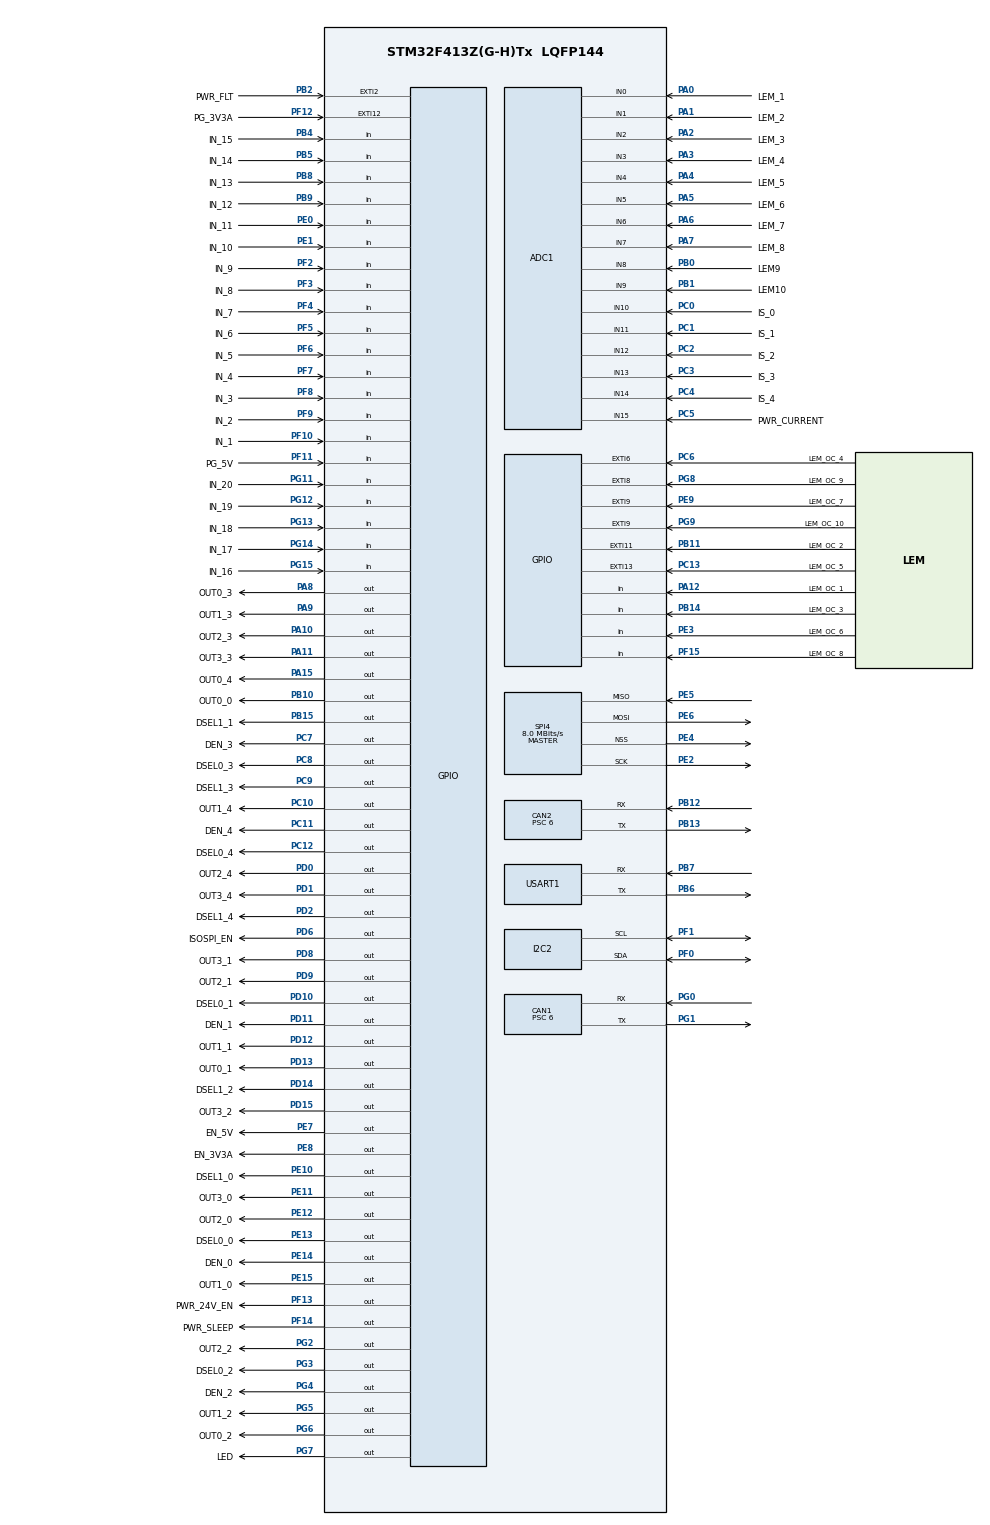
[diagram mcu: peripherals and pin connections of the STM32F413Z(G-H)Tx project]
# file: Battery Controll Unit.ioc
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ADC1.Channel-0\#ChannelRegularConversion=ADC_CHANNEL_0
ADC1.NbrOfConversionFlag=1
ADC1.Rank-0\#ChannelRegularConversion=1
ADC1.SamplingTime-0\#ChannelRegularConversion=ADC_SAMPLETIME_3CYCLES
ADC1.master=1
CAN1.BS1=CAN_BS1_13TQ
CAN1.BS2=CAN_BS2_2TQ
CAN1.CalculateBaudRate=166666
CAN1.CalculateTimeBit=6000
CAN1.CalculateTimeQuantum=375.0
CAN1.Prescaler=6
CAN2.BS1=CAN_BS1_13TQ
CAN2.BS2=CAN_BS2_2TQ
CAN2.CalculateBaudRate=166666
CAN2.CalculateTimeBit=6000
CAN2.CalculateTimeQuantum=375.0
CAN2.Prescaler=6
Mcu.Family=STM32F4
Mcu.Name=STM32F413Z(G-H)Tx
Mcu.Package=LQFP144
NVIC.PriorityGroup=NVIC_PRIORITYGROUP_4
PA0.GPIO_Label=LEM_1
PA0.Signal=ADCx_IN0
PA1.GPIO_Label=LEM_2
PA1.Signal=ADCx_IN1
PA10.GPIO_Label=OUT2_3
PA10.Signal=GPIO_Output
PA11.GPIO_Label=OUT3_3
PA11.Signal=GPIO_Output
PA12.GPIO_Label=LEM_OC_1
PA12.Signal=GPIO_Input
PA13.Mode=Trace_Asynchronous_SW
PA13.Signal=SYS_JTMS-SWDIO
PA14.Mode=Trace_Asynchronous_SW
PA14.Signal=SYS_JTCK-SWCLK
PA15.GPIO_Label=OUT0_4
PA15.Signal=GPIO_Output
PA2.GPIO_Label=LEM_3
PA2.Signal=ADCx_IN2
PA3.GPIO_Label=LEM_4
PA3.Signal=ADCx_IN3
PA4.GPIO_Label=LEM_5
PA4.Signal=ADCx_IN4
PA5.GPIO_Label=LEM_6
PA5.Signal=ADCx_IN5
PA6.GPIO_Label=LEM_7
PA6.Signal=ADCx_IN6
PA7.GPIO_Label=LEM_8
PA7.Signal=ADCx_IN7
PA8.GPIO_Label=OUT0_3
PA8.Signal=GPIO_Output
PA9.GPIO_Label=OUT1_3
PA9.Signal=GPIO_Output
PB0.GPIO_Label=LEM9
PB0.Signal=ADCx_IN8
PB1.GPIO_Label=LEM10
PB1.Signal=ADCx_IN9
PB10.GPIO_Label=OUT0_0
PB10.Signal=GPIO_Output
PB11.GPIO_Label=LEM_OC_2
PB11.Signal=GPXTI11
PB12.Mode=CAN_Activate
PB12.Signal=CAN2_RX
PB13.Mode=CAN_Activate
PB13.Signal=CAN2_TX
PB14.GPIO_Label=LEM_OC_3
PB14.Signal=GPIO_Input
PB15.GPIO_Label=DSEL1_1
PB15.Signal=GPIO_Output
PB2.GPIO_Label=PWR_FLT
PB2.Signal=GPXTI2
PB3.Mode=Trace_Asynchronous_SW
PB3.Signal=SYS_JTDO-SWO
PB4.GPIO_Label=IN_15
PB4.Signal=GPIO_Input
PB5.GPIO_Label=IN_14
PB5.Signal=GPIO_Input
PB6.Mode=Asynchronous
PB6.Signal=USART1_TX
PB7.Mode=Asynchronous
PB7.Signal=USART1_RX
PB8.GPIO_Label=IN_13
PB8.Signal=GPIO_Input
PB9.GPIO_Label=IN_12
PB9.Signal=GPIO_Input
PC0.GPIO_Label=IS_0
PC0.Signal=ADCx_IN10
PC1.GPIO_Label=IS_1
PC1.Signal=ADCx_IN11
PC10.GPIO_Label=OUT1_4
PC10.Signal=GPIO_Output
PC11.GPIO_Label=DEN_4
PC11.Signal=GPIO_Output
PC12.GPIO_Label=DSEL0_4
PC12.Signal=GPIO_Output
PC13.GPIO_Label=LEM_OC_5
PC13.Signal=GPXTI13
PC14-OSC32_IN.Mode=LSE-External-Oscillator
PC14-OSC32_IN.Signal=RCC_OSC32_IN
PC15-OSC32_OUT.Mode=LSE-External-Oscillator
PC15-OSC32_OUT.Signal=RCC_OSC32_OUT
PC2.GPIO_Label=IS_2
PC2.Signal=ADCx_IN12
PC3.GPIO_Label=IS_3
PC3.Signal=ADCx_IN13
PC4.GPIO_Label=IS_4
PC4.Signal=ADCx_IN14
PC5.GPIO_Label=PWR_CURRENT
PC5.Signal=ADCx_IN15
PC6.GPIO_Label=LEM_OC_4
PC6.Signal=GPXTI6
PC7.GPIO_Label=DEN_3
PC7.Signal=GPIO_Output
PC8.GPIO_Label=DSEL0_3
PC8.Signal=GPIO_Output
PC9.GPIO_Label=DSEL1_3
PC9.Signal=GPIO_Output
PD0.GPIO_Label=OUT2_4
PD0.Signal=GPIO_Output
PD1.GPIO_Label=OUT3_4
PD1.Signal=GPIO_Output
PD10.GPIO_Label=DSEL0_1
PD10.Signal=GPIO_Output
PD11.GPIO_Label=DEN_1
PD11.Signal=GPIO_Output
PD12.GPIO_Label=OUT1_1
PD12.Signal=GPIO_Output
PD13.GPIO_Label=OUT0_1
PD13.Signal=GPIO_Output
PD14.GPIO_Label=DSEL1_2
PD14.Signal=GPIO_Output
PD15.GPIO_Label=OUT3_2
PD15.Signal=GPIO_Output
PD2.GPIO_Label=DSEL1_4
PD2.Signal=GPIO_Output
PD6.GPIO_Label=ISOSPI_EN
PD6.Signal=GPIO_Output
PD8.GPIO_Label=OUT3_1
PD8.Signal=GPIO_Output
PD9.GPIO_Label=OUT2_1
PD9.Signal=GPIO_Output
PE0.GPIO_Label=IN_11
PE0.Signal=GPIO_Input
PE1.GPIO_Label=IN_10
PE1.Signal=GPIO_Input
PE10.GPIO_Label=DSEL1_0
PE10.Signal=GPIO_Output
PE11.GPIO_Label=OUT3_0
PE11.Signal=GPIO_Output
PE12.GPIO_Label=OUT2_0
PE12.Signal=GPIO_Output
PE13.GPIO_Label=DSEL0_0
PE13.Signal=GPIO_Output
PE14.GPIO_Label=DEN_0
PE14.Signal=GPIO_Output
PE15.GPIO_Label=OUT1_0
PE15.Signal=GPIO_Output
PE2.Mode=Full_Duplex_Master
PE2.Signal=SPI4_SCK
PE3.GPIO_Label=LEM_OC_6
PE3.Signal=GPIO_Input
PE4.Mode=NSS_Signal_Hard_Output
PE4.Signal=SPI4_NSS
PE5.Mode=Full_Duplex_Master
PE5.Signal=SPI4_MISO
PE6.Mode=Full_Duplex_Master
PE6.Signal=SPI4_MOSI
PE7.GPIO_Label=EN_5V
PE7.Signal=GPIO_Output
PE8.GPIO_Label=EN_3V3A
PE8.Signal=GPIO_Output
PE9.GPIO_Label=LEM_OC_7
PE9.Signal=GPXTI9
PF0.Mode=I2C
PF0.Signal=I2C2_SDA
PF1.Mode=I2C
PF1.Signal=I2C2_SCL
PF10.GPIO_Label=IN_1
PF10.Signal=GPIO_Input
PF11.GPIO_Label=PG_5V
PF11.Signal=GPIO_Input
PF12.GPIO_Label=PG_3V3A
PF12.Signal=GPXTI12
PF13.GPIO_Label=PWR_24V_EN
PF13.Signal=GPIO_Output
PF14.GPIO_Label=PWR_SLEEP
PF14.Signal=GPIO_Output
PF15.GPIO_Label=LEM_OC_8
PF15.Signal=GPIO_Input
PF2.GPIO_Label=IN_9
PF2.Signal=GPIO_Input
PF3.GPIO_Label=IN_8
PF3.Signal=GPIO_Input
PF4.GPIO_Label=IN_7
PF4.Signal=GPIO_Input
PF5.GPIO_Label=IN_6
PF5.Signal=GPIO_Input
PF6.GPIO_Label=IN_5
PF6.Signal=GPIO_Input
PF7.GPIO_Label=IN_4
PF7.Signal=GPIO_Input
PF8.GPIO_Label=IN_3
PF8.Signal=GPIO_Input
PF9.GPIO_Label=IN_2
PF9.Signal=GPIO_Input
PG0.Mode=CAN_Activate
PG0.Signal=CAN1_RX
PG1.Mode=CAN_Activate
PG1.Signal=CAN1_TX
PG11.GPIO_Label=IN_20
PG11.Signal=GPIO_Input
PG12.GPIO_Label=IN_19
PG12.Signal=GPIO_Input
PG13.GPIO_Label=IN_18
PG13.Signal=GPIO_Input
PG14.GPIO_Label=IN_17
PG14.Signal=GPIO_Input
PG15.GPIO_Label=IN_16
PG15.Signal=GPIO_Input
PG2.GPIO_Label=OUT2_2
PG2.Signal=GPIO_Output
PG3.GPIO_Label=DSEL0_2
PG3.Signal=GPIO_Output
PG4.GPIO_Label=DEN_2
PG4.Signal=GPIO_Output
PG5.GPIO_Label=OUT1_2
PG5.Signal=GPIO_Output
PG6.GPIO_Label=OUT0_2
PG6.Signal=GPIO_Output
PG7.GPIO_Label=LED
PG7.Signal=GPIO_Output
PG8.GPIO_Label=LEM_OC_9
PG8.Signal=GPXTI8
PG9.GPIO_Label=LEM_OC_10
PG9.Signal=GPXTI9
PH0\ -\ OSC_IN.Mode=HSE-External-Oscillator
PH0\ -\ OSC_IN.Signal=RCC_OSC_IN
PH1\ -\ OSC_OUT.Mode=HSE-External-Oscillator
PH1\ -\ OSC_OUT.Signal=RCC_OSC_OUT
ProjectManager.HeapSize=0x200
ProjectManager.StackSize=0x400
ProjectManager.TargetToolchain=STM32CubeIDE
RCC.CortexFreq_Value=16000000
RCC.USBFreq_Value=96000000
RCC.VCOOutputFreq_Value=192000000
SH.ADCx_IN0.0=ADC1_IN0,IN0
SH.ADCx_IN1.0=ADC1_IN1,IN1
SH.ADCx_IN10.0=ADC1_IN10,IN10
SH.ADCx_IN11.0=ADC1_IN11,IN11
SH.ADCx_IN12.0=ADC1_IN12,IN12
SH.ADCx_IN13.0=ADC1_IN13,IN13
SH.ADCx_IN14.0=ADC1_IN14,IN14
SH.ADCx_IN15.0=ADC1_IN15,IN15
SH.ADCx_IN2.0=ADC1_IN2,IN2
SH.ADCx_IN3.0=ADC1_IN3,IN3
SH.ADCx_IN4.0=ADC1_IN4,IN4
SH.ADCx_IN5.0=ADC1_IN5,IN5
SH.ADCx_IN6.0=ADC1_IN6,IN6
SH.ADCx_IN7.0=ADC1_IN7,IN7
SH.ADCx_IN8.0=ADC1_IN8,IN8
SH.ADCx_IN9.0=ADC1_IN9,IN9
SPI4.CalculateBaudRate=8.0 MBits/s
SPI4.Direction=SPI_DIRECTION_2LINES
SPI4.Mode=SPI_MODE_MASTER
SPI4.VirtualNSS=VM_NSSHARD
SPI4.VirtualType=VM_MASTER
USART1.VirtualMode=VM_ASYNC
board=custom

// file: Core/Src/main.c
/* USER CODE BEGIN Header */
/**
  ******************************************************************************
  * @file           : main.c
  * @brief          : Main program body
  ******************************************************************************
  * @attention
  *
  * Copyright (c) 2025 STMicroelectronics.
  * All rights reserved.
  *
  * This software is licensed under terms that can be found in the LICENSE file
  * in the root directory of this software component.
  * If no LICENSE file comes with this software, it is provided AS-IS.
  *
  ******************************************************************************
  */
/* USER CODE END Header */
#include "main.h"

/* USER CODE BEGIN Includes */
#include "btt6200_4esa.h"
#include "btt6200_config.h"
#include "tmp1075.h"
#include "cy15b256j.h"
#include "temp_logger.h"
#include "lem_hoys.h"
#include "lem_config.h"
#include "bmu_can.h"
#include "adc_dma.h"
#include "can_diagnostics.h"
#include "dcdc_controller.h"
#include "dcdc_diagnostics.h"
#include <string.h>
#include <stdio.h>
#include <stdlib.h>
#include <stdbool.h>
#include <math.h>

/* USER CODE END Includes */

ADC_HandleTypeDef hadc1;
DMA_HandleTypeDef hdma_adc1;

CAN_HandleTypeDef hcan1;
CAN_HandleTypeDef hcan2;

I2C_HandleTypeDef hi2c2;

SPI_HandleTypeDef hspi4;

UART_HandleTypeDef huart1;

/* USER CODE BEGIN PV */
static TMP1075_HandleTypeDef htmp1075;
static CY15B256J_HandleTypeDef hfram;
static TempLogger_HandleTypeDef htemplogger;
static BMU_CAN_HandleTypeDef hbmucan;
ADC_DMA_HandleTypeDef hadc_dma;  // Non-static - used by lem_hoys.c and btt6200_4esa.c

// CAN message counters
static uint32_t can_heartbeat_counter = 0;

/* USER CODE END PV */

void SystemClock_Config(void);
static void MX_GPIO_Init(void);
static void MX_ADC1_Init(void);
static void MX_CAN1_Init(void);
static void MX_CAN2_Init(void);
static void MX_SPI4_Init(void);
static void MX_USART1_UART_Init(void);
static void MX_I2C2_Init(void);

/* USER CODE BEGIN 0 */

// ADC konstante
#define ADC_VREF_UV            3300000UL  // 3.3V v mikrovolti
#define ADC_BITS               12
#define ADC_MAX_VALUE          4095UL     // (1 << 12) - 1
#define ADC_TO_UV(adc_val)     (((adc_val) * ADC_VREF_UV) / ADC_MAX_VALUE)

// Power sense konstante
#define PWR_SENSE_RESISTOR_MOHM 100      // 0.1 ohm = 100 milliohm
#define PWR_SENSE_GAIN         50
#define PWR_VOLTAGE_DIV        5000UL    // Voltage divider

// I2C adresi
#define TMP1075_I2C_ADDR       (0x48 << 1)
#define FRAM_I2C_ADDR          (0x50 << 1)

// LEM senzorji
#define NUM_LEM_SENSORS        10
#define NUM_ADC_CHANNELS       8

// Timing konstante
#define MAIN_LOOP_DELAY_MS     100
#define CAN_TX_TIMEOUT_MS      100

/* USER CODE END 0 */

int main(void)
{

  /* USER CODE BEGIN 1 */
  char uart_buf[256];  // Povečan buffer za preprečitev overflow

  /* USER CODE END 1 */

  /* MCU Configuration--------------------------------------------------------*/

  /* Reset of all peripherals, Initializes the Flash interface and the Systick. */
  HAL_Init();

  /* Configure the system clock */
  SystemClock_Config();

  /* Initialize all configured peripherals */
  MX_GPIO_Init();
  MX_ADC1_Init();
  MX_CAN1_Init();
  MX_CAN2_Init();
  MX_SPI4_Init();
  MX_USART1_UART_Init();
  MX_I2C2_Init();
  /* USER CODE BEGIN 2 */

  // Debug: Preveri I2C2 devices
  uint8_t msg[] = "\r\n=== BMU IOC Initialization ===\r\n";
  HAL_UART_Transmit(&huart1, msg, sizeof(msg)-1, 100);

  // I2C scan za TMP1075
  if (HAL_I2C_IsDeviceReady(&hi2c2, TMP1075_I2C_ADDR, 3, 100) == HAL_OK) {
      uint8_t found[] = "TMP1075 detected at 0x48\r\n";
      HAL_UART_Transmit(&huart1, found, sizeof(found)-1, 100);
  } else {
      uint8_t notfound[] = "TMP1075 NOT detected at 0x48!\r\n";
      HAL_UART_Transmit(&huart1, notfound, sizeof(notfound)-1, 100);
  }

  // Inicializacija TMP1075
  HAL_StatusTypeDef tmp_status = TMP1075_Init(&htmp1075, &hi2c2, TMP1075_I2C_ADDR >> 1);
  if (tmp_status == HAL_OK) {
      uint8_t init_ok[] = "TMP1075 initialized OK\r\n";
      HAL_UART_Transmit(&huart1, init_ok, sizeof(init_ok)-1, 100);

      // Nastavi low temperature threshold na 0°C (alert pri < 0°C)
      if (TMP1075_SetLowThreshold(&htmp1075, 0.0f) == HAL_OK) {
          uint8_t thresh_ok[] = "Low threshold set to 0.0C\r\n";
          HAL_UART_Transmit(&huart1, thresh_ok, sizeof(thresh_ok)-1, 100);
      }
  } else {
      uint8_t init_fail[] = "TMP1075 initialization FAILED!\r\n";
      HAL_UART_Transmit(&huart1, init_fail, sizeof(init_fail)-1, 100);
  }

  // I2C scan za FRAM CY15B256J
  if (HAL_I2C_IsDeviceReady(&hi2c2, FRAM_I2C_ADDR, 3, 100) == HAL_OK) {
      uint8_t fram_found[] = "FRAM CY15B256J detected at 0x50\r\n";
      HAL_UART_Transmit(&huart1, fram_found, sizeof(fram_found)-1, 100);
  } else {
      uint8_t fram_notfound[] = "FRAM NOT detected at 0x50!\r\n";
      HAL_UART_Transmit(&huart1, fram_notfound, sizeof(fram_notfound)-1, 100);
  }

  // Inicializacija FRAM
  HAL_StatusTypeDef fram_status = CY15B256J_Init(&hfram, &hi2c2, FRAM_I2C_ADDR >> 1, NULL, 0);
  if (fram_status == HAL_OK) {
      uint8_t fram_ok[] = "FRAM initialized OK\r\n";
      HAL_UART_Transmit(&huart1, fram_ok, sizeof(fram_ok)-1, 100);

      // Inicializacija Temperature Logger (reset_stats = false za ohranitev podatkov)
      if (TempLogger_Init(&htemplogger, &hfram, false) == HAL_OK) {
          uint8_t logger_ok[] = "Temperature Logger initialized OK\r\n";
          HAL_UART_Transmit(&huart1, logger_ok, sizeof(logger_ok)-1, 100);

          // Izpiši trenutne statistike
          TempLog_Stats_t stats;
          if (TempLogger_GetStats(&htemplogger, &stats) == HAL_OK) {
              (void)snprintf(uart_buf, sizeof(uart_buf), "Stored samples: %lu, Alerts: %lu\r\n",
                      stats.sample_count, stats.alert_count);
              HAL_UART_Transmit(&huart1, (uint8_t*)uart_buf, strlen(uart_buf), 100);

              if (stats.sample_count > 0U) {
                  int32_t min_frac = stats.min_temp % 100;
                  int32_t max_frac = stats.max_temp % 100;
                  min_frac = (min_frac < 0) ? -min_frac : min_frac;
                  max_frac = (max_frac < 0) ? -max_frac : max_frac;
                  (void)snprintf(uart_buf, sizeof(uart_buf), "Min: %d.%02dC, Max: %d.%02dC\r\n",
                          (int)(stats.min_temp/100), (int)min_frac,
                          (int)(stats.max_temp/100), (int)max_frac);
                  (void)HAL_UART_Transmit(&huart1, (uint8_t*)uart_buf, (uint16_t)strlen(uart_buf), 100);
              }
          }
      }
  } else {
      uint8_t fram_fail[] = "FRAM initialization FAILED!\r\n";
      HAL_UART_Transmit(&huart1, fram_fail, sizeof(fram_fail)-1, 100);
  }

  /* Inicializacija LEM HOYS current sensorjev */
  uint8_t lem_msg[] = "\r\n=== LEM HOYS Current Sensors ===\r\n";
  HAL_UART_Transmit(&huart1, lem_msg, sizeof(lem_msg)-1, 100);

  if (LEM_Config_Init(&hadc1) == HAL_OK) {
      uint8_t lem_ok[] = "LEM sensors initialized OK\r\n";
      HAL_UART_Transmit(&huart1, lem_ok, sizeof(lem_ok)-1, 100);

      // Kalibriraj vse senzorje (POMEMBNO: mora biti 0A!)
      uint8_t cal_msg[] = "Calibrating LEM sensors (ensure 0A)...\r\n";
      HAL_UART_Transmit(&huart1, cal_msg, sizeof(cal_msg)-1, 100);

      if (LEM_Config_CalibrateAll(50) == HAL_OK) {
          uint8_t cal_ok[] = "LEM calibration complete\r\n";
          HAL_UART_Transmit(&huart1, cal_ok, sizeof(cal_ok)-1, 100);
      } else {
          uint8_t cal_fail[] = "LEM calibration FAILED!\r\n";
          HAL_UART_Transmit(&huart1, cal_fail, sizeof(cal_fail)-1, 100);
      }
  } else {
      uint8_t lem_fail[] = "LEM initialization FAILED!\r\n";
      HAL_UART_Transmit(&huart1, lem_fail, sizeof(lem_fail)-1, 100);
  }

  /* Inicializacija CAN protokola (500 kbps) */
  uint8_t can_msg[] = "\r\n=== CAN Bus Protocol ===\r\n";
  HAL_UART_Transmit(&huart1, can_msg, sizeof(can_msg)-1, 100);

  // Debug: Preveri CAN1 state pred inicializacijo
  (void)snprintf(uart_buf, sizeof(uart_buf), "CAN1 State before init: 0x%02X\r\n", hcan1.State);
  HAL_UART_Transmit(&huart1, (uint8_t*)uart_buf, strlen(uart_buf), 100);

  /* TESTING MODE: Set to 1 to enable LOOPBACK mode (test without other CAN nodes) */
  #if 0
  // Switch CAN2 to LOOPBACK mode for solo testing without ACK errors
  uint8_t loopback_msg[] = "*** CAN2 LOOPBACK MODE ENABLED ***\r\n";
  HAL_UART_Transmit(&huart1, loopback_msg, sizeof(loopback_msg)-1, 100);
  uint8_t loopback_info[] = "CAN2 will TX and RX its own messages (no external bus needed)\r\n";
  HAL_UART_Transmit(&huart1, loopback_info, sizeof(loopback_info)-1, 100);

  hcan2.Init.Mode = CAN_MODE_LOOPBACK;  // LOOPBACK: TX -> RX internally
  if (HAL_CAN_Init(&hcan2) != HAL_OK) {
      uint8_t err[] = "Failed to switch CAN2 to LOOPBACK mode!\r\n";
      HAL_UART_Transmit(&huart1, err, sizeof(err)-1, 100);
  } else {
      uint8_t ok[] = "CAN2 LOOPBACK mode configured successfully\r\n";
      HAL_UART_Transmit(&huart1, ok, sizeof(ok)-1, 100);
  }
  #endif

  if (BMU_CAN_Init(&hbmucan, &hcan1, &hcan2) == HAL_OK) {
      uint8_t can_ok[] = "CAN bus initialized OK (500 kbps)\r\n";
      HAL_UART_Transmit(&huart1, can_ok, sizeof(can_ok)-1, 100);

      /* TEST CAN1 TX: Standard ID test */
      {
          CAN_TxHeaderTypeDef test_header;
          uint8_t test_data[8] = {0x11, 0x22, 0x33, 0x44, 0x55, 0x66, 0x77, 0x88};
          uint32_t test_mailbox;
          HAL_StatusTypeDef test_status;

          uint8_t test_msg[] = "\r\n>>> CAN1 TEST TX START <<<\r\n";
          HAL_UART_Transmit(&huart1, test_msg, sizeof(test_msg)-1, 100);

          /* Standard ID test message */
          test_header.StdId = 0x123;  /* Test Standard ID */
          test_header.IDE = CAN_ID_STD;
          test_header.RTR = CAN_RTR_DATA;
          test_header.DLC = 8;
          test_header.TransmitGlobalTime = DISABLE;

          test_status = HAL_CAN_AddTxMessage(&hcan1, &test_header, test_data, &test_mailbox);

          if (test_status == HAL_OK) {
              (void)snprintf(uart_buf, sizeof(uart_buf),
                  "✓ CAN1 TEST TX SUCCESS! StdID:0x%03lX Mailbox:%lu\r\n",
                  test_header.StdId, test_mailbox);
              HAL_UART_Transmit(&huart1, (uint8_t*)uart_buf, strlen(uart_buf), 100);
          } else {
              (void)snprintf(uart_buf, sizeof(uart_buf),
                  "✗ CAN1 TEST TX FAILED! Status:%d\r\n", test_status);
              HAL_UART_Transmit(&huart1, (uint8_t*)uart_buf, strlen(uart_buf), 100);
          }

          uint8_t test_end[] = ">>> CAN1 TEST TX END <<<\r\n\r\n";
          HAL_UART_Transmit(&huart1, test_end, sizeof(test_end)-1, 100);
      }

      /* TEST CAN2 TX: Extended ID test */
      {
          CAN_TxHeaderTypeDef test_header;
          uint8_t test_data[8] = {0xAA, 0xBB, 0xCC, 0xDD, 0x11, 0x22, 0x33, 0x44};
          uint32_t test_mailbox;
          HAL_StatusTypeDef test_status;

          uint8_t test_msg[] = ">>> CAN2 TEST TX START <<<\r\n";
          HAL_UART_Transmit(&huart1, test_msg, sizeof(test_msg)-1, 100);

          /* Extended ID test message */
          test_header.ExtId = 0x18FF5500;  /* Test Extended ID */
          test_header.IDE = CAN_ID_EXT;
          test_header.RTR = CAN_RTR_DATA;
          test_header.DLC = 8;
          test_header.TransmitGlobalTime = DISABLE;

          /* Check CAN2 state before sending */
          (void)snprintf(uart_buf, sizeof(uart_buf), "CAN2 State: 0x%02X\r\n", hcan2.State);
          HAL_UART_Transmit(&huart1, (uint8_t*)uart_buf, strlen(uart_buf), 100);

          uint32_t can2_error = HAL_CAN_GetError(&hcan2);
          (void)snprintf(uart_buf, sizeof(uart_buf), "CAN2 Error: 0x%08lX\r\n", can2_error);
          HAL_UART_Transmit(&huart1, (uint8_t*)uart_buf, strlen(uart_buf), 100);

          uint32_t free_boxes = HAL_CAN_GetTxMailboxesFreeLevel(&hcan2);
          (void)snprintf(uart_buf, sizeof(uart_buf), "CAN2 Free TX Mailboxes: %lu\r\n", free_boxes);
          HAL_UART_Transmit(&huart1, (uint8_t*)uart_buf, strlen(uart_buf), 100);

          /* Send test message on CAN2 */
          test_status = HAL_CAN_AddTxMessage(&hcan2, &test_header, test_data, &test_mailbox);

          if (test_status == HAL_OK) {
              (void)snprintf(uart_buf, sizeof(uart_buf),
                  "✓ CAN2 AddTxMessage OK! ExtID:0x%08lX Mailbox:%lu\r\n",
                  test_header.ExtId, test_mailbox);
              HAL_UART_Transmit(&huart1, (uint8_t*)uart_buf, strlen(uart_buf), 100);

              /* Wait for TX to complete and check result */
              HAL_Delay(100);  /* Give time for TX to complete */

              can2_error = HAL_CAN_GetError(&hcan2);
              (void)snprintf(uart_buf, sizeof(uart_buf), "CAN2 Error after TX attempt: 0x%08lX\r\n", can2_error);
              HAL_UART_Transmit(&huart1, (uint8_t*)uart_buf, strlen(uart_buf), 100);

              /* Decode CAN2 error codes */
              if (can2_error == 0x00000000UL) {
                  uint8_t ok[] = "✓ NO ERRORS - CAN2 TX successful!\r\n";
                  HAL_UART_Transmit(&huart1, ok, sizeof(ok)-1, 100);
              } else {
                  if ((can2_error & 0x00000004UL) != 0UL) {  /* HAL_CAN_ERROR_ACK */
                      uint8_t ack_err[] = "✗ ACK ERROR - No device on bus acknowledged message!\r\n";
                      HAL_UART_Transmit(&huart1, ack_err, sizeof(ack_err)-1, 100);
                      uint8_t ack_fix[] = "  FIX: Connect another CAN device OR enable LOOPBACK mode\r\n";
                      HAL_UART_Transmit(&huart1, ack_fix, sizeof(ack_fix)-1, 100);
                  }
                  if ((can2_error & 0x00000010UL) != 0UL) {  /* HAL_CAN_ERROR_BOF */
                      uint8_t bof_err[] = "✗ BUS-OFF - Too many errors, CAN2 disabled!\r\n";
                      HAL_UART_Transmit(&huart1, bof_err, sizeof(bof_err)-1, 100);
                  }
                  if ((can2_error & 0x00000001UL) != 0UL) {  /* HAL_CAN_ERROR_EWG */
                      uint8_t ewg_err[] = "⚠ ERROR WARNING - Error count high\r\n";
                      HAL_UART_Transmit(&huart1, ewg_err, sizeof(ewg_err)-1, 100);
                  }
              }
          } else {
              (void)snprintf(uart_buf, sizeof(uart_buf),
                  "✗ CAN2 AddTxMessage FAILED! Status:%d\r\n", test_status);
              HAL_UART_Transmit(&huart1, (uint8_t*)uart_buf, strlen(uart_buf), 100);

              /* Print detailed error */
              can2_error = HAL_CAN_GetError(&hcan2);
              (void)snprintf(uart_buf, sizeof(uart_buf), "CAN2 Error code: 0x%08lX\r\n", can2_error);
              HAL_UART_Transmit(&huart1, (uint8_t*)uart_buf, strlen(uart_buf), 100);
          }

          uint8_t test_end[] = ">>> CAN2 TEST TX END <<<\r\n\r\n";
          HAL_UART_Transmit(&huart1, test_end, sizeof(test_end)-1, 100);
      }

      // Debug: Preveri CAN1 error code
      uint32_t can_error = HAL_CAN_GetError(&hcan1);
      (void)snprintf(uart_buf, sizeof(uart_buf), "CAN1 Error Code: 0x%08lX\r\n", can_error);
      HAL_UART_Transmit(&huart1, (uint8_t*)uart_buf, strlen(uart_buf), 100);

      /* DIAGNOSTICS: Set to 0 to disable diagnostics for testing */
      #if 0  // DISABLED for debugging - diagnostika lahko povzroča probleme
      CAN_RunDiagnostics(&hcan1, &huart1);
      #else
      uint8_t diag_skip[] = "CAN diagnostics SKIPPED (disabled for debugging)\r\n";
      HAL_UART_Transmit(&huart1, diag_skip, sizeof(diag_skip)-1, 100);
      #endif
  } else {
      uint8_t can_fail[] = "CAN initialization FAILED!\r\n";
      HAL_UART_Transmit(&huart1, can_fail, sizeof(can_fail)-1, 100);

      // Debug: Izpiši error code
      uint32_t can_error = HAL_CAN_GetError(&hcan1);
      (void)snprintf(uart_buf, sizeof(uart_buf), "CAN1 Error Code: 0x%08lX\r\n", can_error);
      HAL_UART_Transmit(&huart1, (uint8_t*)uart_buf, strlen(uart_buf), 100);
      (void)snprintf(uart_buf, sizeof(uart_buf), "CAN1 State: 0x%02X\r\n", hcan1.State);
      HAL_UART_Transmit(&huart1, (uint8_t*)uart_buf, strlen(uart_buf), 100);
  }

  /* Inicializacija ADC DMA - avtomatsko kontinuirano branje vseh 16 kanalov */
  if (ADC_DMA_Init(&hadc_dma, &hadc1, &hdma_adc1) == HAL_OK) {
    ADC_DMA_Start(&hadc_dma);
  }

  /* inicializacija BTT6200 modulov */
  BTT6200_Config_Init(&hadc1);   // ali &hadc, isto kot si nastavil v config.c
  BTT6200_Init(&btt6200_modules[0]);

  /* Inicializacija DC/DC kontrolerja (CAN2) */
  uint8_t dcdc_msg[] = "\r\n=== DC/DC Converter Control ===\r\n";
  HAL_UART_Transmit(&huart1, dcdc_msg, sizeof(dcdc_msg)-1, 100);

  if (DCDC_Init()) {
      uint8_t dcdc_ok[] = "DC/DC controller initialized OK\r\n";
      HAL_UART_Transmit(&huart1, dcdc_ok, sizeof(dcdc_ok)-1, 100);

      /* Konfiguriraj oba pretvornika: 24V, 10A, Bus1toBus2 */
      DCDC_Config_t dcdc_config;
      dcdc_config.converter_mode = DCDC_MODE_BUS1_TO_BUS2;
      dcdc_config.control_type = DCDC_CTRL_TYPE_VBUS2_LIM;
      dcdc_config.voltage_setpoint = DCDC_SETPOINT_24V;    /* 24.0V */
      dcdc_config.current_limit = DCDC_CURRENT_LIMIT_10A;  /* 10.0A */
      dcdc_config.start_command = DCDC_CMD_STOP;           /* Začni v STOP */

      if (DCDC_Configure(0, &dcdc_config) && DCDC_Configure(1, &dcdc_config)) {
          uint8_t dcdc_cfg_ok[] = "DC/DC converters configured: 24V, 10A, Bus1toBus2\r\n";
          HAL_UART_Transmit(&huart1, dcdc_cfg_ok, sizeof(dcdc_cfg_ok)-1, 100);

          /* AKTIVIRAJ CAN2 TX: Start oba pretvornika za testiranje */
          if (DCDC_Start(0) && DCDC_Start(1)) {
              uint8_t dcdc_start_ok[] = "DC/DC converters STARTED - CAN2 TX active!\r\n";
              HAL_UART_Transmit(&huart1, dcdc_start_ok, sizeof(dcdc_start_ok)-1, 100);
          } else {
              uint8_t dcdc_start_fail[] = "WARNING: DC/DC start failed - CAN2 TX inactive!\r\n";
              HAL_UART_Transmit(&huart1, dcdc_start_fail, sizeof(dcdc_start_fail)-1, 100);
          }
      }
  } else {
      uint8_t dcdc_fail[] = "DC/DC controller initialization FAILED!\r\n";
      HAL_UART_Transmit(&huart1, dcdc_fail, sizeof(dcdc_fail)-1, 100);
  }

  /* Inicializacija DC/DC diagnostike (CAN1) */
  if (DCDC_Diag_Init()) {
      uint8_t diag_ok[] = "DC/DC diagnostics initialized OK (CAN1)\r\n";
      HAL_UART_Transmit(&huart1, diag_ok, sizeof(diag_ok)-1, 100);
  }

  uint8_t ready[] = "\r\n*** System Ready ***\r\n\r\n";
  HAL_UART_Transmit(&huart1, ready, sizeof(ready)-1, 100);

  /* USER CODE END 2 */

  /* Infinite loop */
  /* USER CODE BEGIN WHILE */
  uint32_t loop_iteration = 0;
  uint32_t last_slow_task_tick = 0;  /* Timestamp za počasne naloge (1Hz) */

  while (1)
  {
    /* USER CODE END WHILE */

    /* USER CODE BEGIN 3 */
	  uint32_t current_tick = HAL_GetTick();
	  bool execute_slow_tasks = false;

	  /* Preveri če je čas za počasne naloge (1x na sekundo) */
	  if ((current_tick - last_slow_task_tick) >= 1000U) {
	      execute_slow_tasks = true;
	      last_slow_task_tick = current_tick;
	      loop_iteration++;
	  }

	  /* HITRE NALOGE: Izvajaj vsakih 10-20ms */

	  // ========== DC/DC Periodic Tasks (20ms timing interno) ==========
	  DCDC_PeriodicTask();         /* CAN2: Control frame vsakih 20ms */
	  DCDC_Diag_PeriodicTask();    /* CAN1: Diagnostika vsakih 100ms */

	  /* POČASNE NALOGE: Izvajaj 1x na sekundo */
	  if (execute_slow_tasks) {
	      float tC;
	      int16_t temp_x100;
	      bool is_alert;

	      // Debug output (samo vsakih 10 sekund)
	      if (loop_iteration % 10U == 1U) {
	          (void)snprintf(uart_buf, sizeof(uart_buf), "\r\n=== Loop %lu ===\r\n", loop_iteration);
	          HAL_UART_Transmit(&huart1, (uint8_t*)uart_buf, strlen(uart_buf), 100);
	      }

	      HAL_GPIO_WritePin(PWR_24V_EN_GPIO_Port, PWR_24V_EN_Pin, SET);
	      HAL_GPIO_WritePin(PWR_SLEEP_GPIO_Port, PWR_SLEEP_Pin, SET);
	      HAL_GPIO_TogglePin(LED_GPIO_Port, LED_Pin);  // LED toggle za heartbeat

	      // Preberi in izpiši temperaturo
	      tC = 0.0f;
	      temp_x100 = 0;
	      is_alert = false;
	      if (TMP1075_ReadTemperature(&htmp1075, &tC) == HAL_OK) {
	          // Uspešno branje temperature
	          int32_t temp_int = (int32_t)tC;
	          int32_t temp_frac = (int32_t)((tC - (float)temp_int) * 100.0f);
	          if (temp_frac < 0) {
	              temp_frac = -temp_frac;  // Absolutna vrednost za decimale
	          }

	          // Konvertiraj v int16_t (°C × 100) za shranjevanje v FRAM
	          temp_x100 = (int16_t)(tC * 100.0f);
	          is_alert = (tC < 0.0f);

	          // Shrani v FRAM (če je inicializiran)
	          if (htemplogger.is_initialized != false) {
	              (void)TempLogger_LogTemperature(&htemplogger, temp_x100, is_alert);
	          }

	          // ALERT: Temperatura pod 0°C
	          if (is_alert) {
	              (void)snprintf(uart_buf, sizeof(uart_buf), "*** ALERT! Temperature: %d.%02d C (BELOW 0C!) ***\r\n", temp_int, temp_frac);
	              HAL_UART_Transmit(&huart1, (uint8_t*)uart_buf, strlen(uart_buf), 100);
	              // Prižgi LED - hitro utripanje za alarm
	              HAL_GPIO_WritePin(LED_GPIO_Port, LED_Pin, SET);
	              HAL_Delay(100);
	              HAL_GPIO_WritePin(LED_GPIO_Port, LED_Pin, RESET);
	              HAL_Delay(100);
	              HAL_GPIO_WritePin(LED_GPIO_Port, LED_Pin, SET);
	          } else {
	              (void)snprintf(uart_buf, sizeof(uart_buf), "Temperature: %d.%02d C\r\n", temp_int, temp_frac);
	              HAL_UART_Transmit(&huart1, (uint8_t*)uart_buf, strlen(uart_buf), 100);
	          }
	      } else {
	          uint8_t err[] = "Temperature read FAILED!\r\n";
	          HAL_UART_Transmit(&huart1, err, sizeof(err)-1, 100);
	      }

	        // ADC DMA Debug: Prikaz ADC surovih vrednosti in DMA statistike
	        #if 0  // Set to 1 to enable ADC DMA debug output
	        if (hadc_dma.is_initialized) {
	            uint32_t conv_count, error_count;
	            if (ADC_DMA_GetStats(&hadc_dma, &conv_count, &error_count) == HAL_OK) {
	                (void)snprintf(uart_buf, sizeof(uart_buf), "[ADC DMA] Conv: %lu, Errors: %lu\r\n", conv_count, error_count);
	                HAL_UART_Transmit(&huart1, (uint8_t*)uart_buf, strlen(uart_buf), 100);
	            }

	            // Prikaz surovih ADC vrednosti za LEM senzorje 1-3
	            uint16_t adc_value;
	            for (uint8_t i = 0; i < 3; i++) {
	                if (ADC_DMA_GetValue(&hadc_dma, (ADC_DMA_Channel_t)i, &adc_value) == HAL_OK) {
	                    (void)snprintf(uart_buf, sizeof(uart_buf), "ADC_CH%d: %4u  ", i, adc_value);
	                    HAL_UART_Transmit(&huart1, (uint8_t*)uart_buf, strlen(uart_buf), 100);
	                }
	            }
	            uint8_t nl[] = "\r\n";
	            HAL_UART_Transmit(&huart1, nl, sizeof(nl)-1, 100);
	        }
	        #endif

	        // Preberi LEM sensorje (prikaz prvih 3 za demo)
	        float lem_currents[3];
	        for (uint8_t i = 0; i < 3; i++) {
	            if (LEM_Config_ReadCurrentFiltered(i, &lem_currents[i]) == HAL_OK) {
	                int curr_int = (int)lem_currents[i];
	                int curr_frac = (int)(fabsf(lem_currents[i] - curr_int) * 1000);
	                (void)snprintf(uart_buf, sizeof(uart_buf), "LEM_%d: %d.%03d A  ", i+1, curr_int, curr_frac);
	                HAL_UART_Transmit(&huart1, (uint8_t*)uart_buf, strlen(uart_buf), 100);
	            }
	        }
	        uint8_t newline[] = "\r\n";
	        HAL_UART_Transmit(&huart1, newline, sizeof(newline)-1, 100);

	        // Preveri overcurrent na vseh LEM senzorjih
	        uint16_t oc_flags = 0;
	        LEM_Config_CheckOvercurrents(&oc_flags);
	        if (oc_flags != 0) {
	            (void)snprintf(uart_buf, sizeof(uart_buf), "*** OVERCURRENT DETECTED! Flags: 0x%04X ***\r\n", oc_flags);
	            HAL_UART_Transmit(&huart1, (uint8_t*)uart_buf, strlen(uart_buf), 100);
	        }

	        // ========== CAN Bus Data Transmission ==========
	        // Check and recover from CAN errors (BUS-OFF, etc.)
	        if (hbmucan.is_initialized) {
	            BMU_CAN_CheckAndRecover(&hbmucan);
	        }

	        // Debug: Check CAN state (only print every 10th or if error detected)
	        HAL_CAN_StateTypeDef can_state = HAL_CAN_GetState(&hcan1);
	        uint32_t free_mailboxes = HAL_CAN_GetTxMailboxesFreeLevel(&hcan1);
	        uint32_t can_error = HAL_CAN_GetError(&hcan1);

	        if (loop_iteration % 10 == 1 || can_error != 0) {
	            (void)snprintf(uart_buf, sizeof(uart_buf), "[CAN] Init:%d State:0x%02X FreeMB:%lu Err:0x%lX\r\n",
	                          hbmucan.is_initialized, can_state, free_mailboxes, can_error);
	            HAL_UART_Transmit(&huart1, (uint8_t*)uart_buf, strlen(uart_buf), 10);
	        }

	        if (hbmucan.is_initialized) {
	            // Only print TX start message every 10th iteration
	            if (loop_iteration % 10 == 1) {
	                uint8_t tx_start[] = "[CAN] TX sequence...\r\n";
	                HAL_UART_Transmit(&huart1, tx_start, sizeof(tx_start)-1, 10);
	            }
	            // 1. Pošlji Temperature message (0x101)
	            BMU_Temperature_Msg_t temp_msg = {0};
	            temp_msg.temperature_C = temp_x100;
	            temp_msg.alert_flag = is_alert ? 1 : 0;
	            temp_msg.sensor_status = 0;
	            if (htemplogger.is_initialized) {
	                TempLog_Stats_t stats;
	                if (TempLogger_GetStats(&htemplogger, &stats) == HAL_OK) {
	                    temp_msg.min_temp_C = stats.min_temp;
	                    temp_msg.max_temp_C = stats.max_temp;
	                }
	            }
	            BMU_CAN_SendTemperature(&hbmucan, &temp_msg);

	            // 2. Pošlji Power Supply Status (0x102)
	            BMU_PowerSupply_Msg_t pwr_msg = {0};
	            pwr_msg.pg_5v = HAL_GPIO_ReadPin(PG_5V_GPIO_Port, PG_5V_Pin);
	            pwr_msg.pg_3v3a = HAL_GPIO_ReadPin(PG_3V3A_GPIO_Port, PG_3V3A_Pin);
	            pwr_msg.pwr_sleep_state = HAL_GPIO_ReadPin(PWR_SLEEP_GPIO_Port, PWR_SLEEP_Pin);

	            /* PWR_CURRENT: Read from ADC_IN15 (PC5) via DMA
	             * PWR_VOLTAGE: Not configured in hardware - using nominal value
	             *
	             * NOTE: Za pravo merjenje 24V napetosti je potreben:
	             * 1. Voltage divider circuit (npr. 10k/1k = 11:1 ratio za 24V->2.18V)
	             * 2. Dodaten ADC kanal v CubeMX konfiguraciji
	             * 3. Kalibracija voltage divider faktorja
	             */

	            // Read PWR_CURRENT from ADC DMA buffer (IN15)
	            uint16_t pwr_current_adc = 0;
	            if (hadc_dma.is_initialized) {
	                ADC_DMA_GetValue(&hadc_dma, ADC_DMA_PWR_CURRENT, &pwr_current_adc);
	            }

	            // Convert ADC to current (assuming current sense resistor circuit)
	            // TODO: Adjust conversion factor based on hardware design
	            // Typical: V_adc = (I_load * R_sense * Gain) where R_sense ~0.1 ohm, Gain=50
	            // I_load = V_adc / (R_sense * Gain)
	            // For 3.3V ref, 12-bit ADC: V_adc = (adc_value * 3300) / 4095
	            uint32_t voltage_uV = ADC_TO_UV(pwr_current_adc);
	            pwr_msg.pwr_current_mA = (uint16_t)(voltage_uV / PWR_VOLTAGE_DIV);  // R_sense*Gain = 0.1*50 = 5

	            // PWR_VOLTAGE: Use nominal value (no ADC sensing configured)
	            // Alternative: Could monitor PG_24V flag and return 0 if power fault
	            pwr_msg.pwr_voltage_mV = 24000U;  // Nominal 24V (hardware sensing not implemented)
	            pwr_msg.pg_24v = (pwr_msg.pwr_voltage_mV > 20000U) ? 1U : 0U;
	            BMU_CAN_SendPowerSupply(&hbmucan, &pwr_msg);

	            // 3. Pošlji Input States (0x103)
	            BMU_InputStates_Msg_t input_msg = {0};
	            input_msg.input_states = 0;
	            // Preberi vseh 20 digitalnih inputov (IN_1 do IN_20)
	            // OPOMBA: Za optimizacijo bi lahko uporabili direkten dostop do GPIO IDR register,
	            // če so vsi pini na istem portu. Trenutna implementacija je generična.
	            if (HAL_GPIO_ReadPin(IN_1_GPIO_Port, IN_1_Pin)) input_msg.input_states |= (1 << 0);
	            if (HAL_GPIO_ReadPin(IN_2_GPIO_Port, IN_2_Pin)) input_msg.input_states |= (1 << 1);
	            if (HAL_GPIO_ReadPin(IN_3_GPIO_Port, IN_3_Pin)) input_msg.input_states |= (1 << 2);
	            if (HAL_GPIO_ReadPin(IN_4_GPIO_Port, IN_4_Pin)) input_msg.input_states |= (1 << 3);
	            if (HAL_GPIO_ReadPin(IN_5_GPIO_Port, IN_5_Pin)) input_msg.input_states |= (1 << 4);
	            if (HAL_GPIO_ReadPin(IN_6_GPIO_Port, IN_6_Pin)) input_msg.input_states |= (1 << 5);
	            if (HAL_GPIO_ReadPin(IN_7_GPIO_Port, IN_7_Pin)) input_msg.input_states |= (1 << 6);
	            if (HAL_GPIO_ReadPin(IN_8_GPIO_Port, IN_8_Pin)) input_msg.input_states |= (1 << 7);
	            if (HAL_GPIO_ReadPin(IN_9_GPIO_Port, IN_9_Pin)) input_msg.input_states |= (1 << 8);
	            if (HAL_GPIO_ReadPin(IN_10_GPIO_Port, IN_10_Pin)) input_msg.input_states |= (1 << 9);
	            if (HAL_GPIO_ReadPin(IN_11_GPIO_Port, IN_11_Pin)) input_msg.input_states |= (1 << 10);
	            if (HAL_GPIO_ReadPin(IN_12_GPIO_Port, IN_12_Pin)) input_msg.input_states |= (1 << 11);
	            if (HAL_GPIO_ReadPin(IN_13_GPIO_Port, IN_13_Pin)) input_msg.input_states |= (1 << 12);
	            if (HAL_GPIO_ReadPin(IN_14_GPIO_Port, IN_14_Pin)) input_msg.input_states |= (1 << 13);
	            if (HAL_GPIO_ReadPin(IN_15_GPIO_Port, IN_15_Pin)) input_msg.input_states |= (1 << 14);
	            if (HAL_GPIO_ReadPin(IN_16_GPIO_Port, IN_16_Pin)) input_msg.input_states |= (1 << 15);
	            if (HAL_GPIO_ReadPin(IN_17_GPIO_Port, IN_17_Pin)) input_msg.input_states |= (1 << 16);
	            if (HAL_GPIO_ReadPin(IN_18_GPIO_Port, IN_18_Pin)) input_msg.input_states |= (1 << 17);
	            if (HAL_GPIO_ReadPin(IN_19_GPIO_Port, IN_19_Pin)) input_msg.input_states |= (1 << 18);
	            if (HAL_GPIO_ReadPin(IN_20_GPIO_Port, IN_20_Pin)) input_msg.input_states |= (1 << 19);
	            BMU_CAN_SendInputStates(&hbmucan, &input_msg);

	            // 4. Pošlji LEM Current messages (0x110-0x112) - FIXED
	            float all_lem_currents[NUM_LEM_SENSORS];
	            LEM_Config_ReadAllCurrents(all_lem_currents);

	            BMU_LEM_Current_Msg_t lem_msg1 = {0};
	            lem_msg1.current_1_mA = (int16_t)(all_lem_currents[0] * 1000);
	            lem_msg1.current_2_mA = (int16_t)(all_lem_currents[1] * 1000);
	            lem_msg1.current_3_mA = (int16_t)(all_lem_currents[2] * 1000);
	            lem_msg1.current_4_mA = (int16_t)(all_lem_currents[3] * 1000);
	            BMU_CAN_SendLEMCurrent(&hbmucan, CAN_ID_LEM_CURRENT_1, &lem_msg1);

	            BMU_LEM_Current_Msg_t lem_msg2 = {0};
	            lem_msg2.current_1_mA = (int16_t)(all_lem_currents[4] * 1000);
	            lem_msg2.current_2_mA = (int16_t)(all_lem_currents[5] * 1000);
	            lem_msg2.current_3_mA = (int16_t)(all_lem_currents[6] * 1000);
	            lem_msg2.current_4_mA = (int16_t)(all_lem_currents[7] * 1000);
	            BMU_CAN_SendLEMCurrent(&hbmucan, CAN_ID_LEM_CURRENT_2, &lem_msg2);

	            BMU_LEM_Current_Msg_t lem_msg3 = {0};
	            lem_msg3.current_1_mA = (int16_t)(all_lem_currents[8] * 1000);
	            lem_msg3.current_2_mA = (int16_t)(all_lem_currents[9] * 1000);
	            lem_msg3.current_3_mA = 0;
	            lem_msg3.current_4_mA = 0;
	            BMU_CAN_SendLEMCurrent(&hbmucan, CAN_ID_LEM_CURRENT_3, &lem_msg3);

	            // 5. Pošlji BTT6200 Detailed Status (0x124-0x128) - vseh 20 outputov
	            for (uint8_t msg_idx = 0; msg_idx < 5; msg_idx++) {
	                BMU_BTT6200_Detailed_Msg_t btt_detail = {0};
	                uint8_t base_out = msg_idx * 4;

	                // STATUS_OK means channel is enabled and working
	                btt_detail.out0_state = (BTT6200_Config_GetStatus(base_out + 0) == BTT6200_STATUS_OK) ? 1U : 0U;
	                btt_detail.out1_state = (BTT6200_Config_GetStatus(base_out + 1) == BTT6200_STATUS_OK) ? 1U : 0U;
	                btt_detail.out2_state = (BTT6200_Config_GetStatus(base_out + 2) == BTT6200_STATUS_OK) ? 1U : 0U;
	                btt_detail.out3_state = (BTT6200_Config_GetStatus(base_out + 3) == BTT6200_STATUS_OK) ? 1U : 0U;

	                uint32_t curr_mA;
	                BTT6200_Config_ReadCurrent(base_out + 0, &curr_mA);
	                btt_detail.out0_current_mA = (uint16_t)curr_mA;
	                BTT6200_Config_ReadCurrent(base_out + 1, &curr_mA);
	                btt_detail.out1_current_mA = (uint16_t)curr_mA;

	                BMU_CAN_SendBTTDetailed(&hbmucan, CAN_ID_BTT6200_DETAIL_1 + msg_idx, &btt_detail);
	            }

	            // 6. Pošlji Heartbeat (0x1FF)
	            BMU_CAN_SendHeartbeat(&hbmucan, can_heartbeat_counter++);

	            // Debug: CAN TX complete - print stats only every 10th iteration
	            if (loop_iteration % 10 == 1) {
	                uint32_t tx_count, rx_count, err_count;
	                BMU_CAN_GetStats(&hbmucan, &tx_count, &rx_count, &err_count);
	                (void)snprintf(uart_buf, sizeof(uart_buf), "[CAN] Stats: TX:%lu RX:%lu ERR:%lu\r\n",
	                              tx_count, rx_count, err_count);
	                HAL_UART_Transmit(&huart1, (uint8_t*)uart_buf, strlen(uart_buf), 10);
	            }
	        } else {
	            uint8_t not_init[] = "[CAN] NOT INITIALIZED - skipping TX!\r\n";
	            HAL_UART_Transmit(&huart1, not_init, sizeof(not_init)-1, 100);
	        }

	  }  /* Konec execute_slow_tasks bloka */

	  // ========== Main Loop Delay ==========
	  /* KRITIČNO: Kratek delay (10ms) za 50Hz loop rate */
	  /* To omogoči DCDC_PeriodicTask() pošiljanje na 20ms! */
	  HAL_Delay(10);

#if 0  /* TEST CODE - Disabled for production */
	  // BTT6200 channel test sequence (enable manually for testing)
	  BTT6200_SetChannel(&btt6200_modules[0], BTT6200_CH0, true);
	  BTT6200_SetChannel(&btt6200_modules[0], BTT6200_CH1, true);
	  BTT6200_SetChannel(&btt6200_modules[0], BTT6200_CH2, true);
	  BTT6200_SetChannel(&btt6200_modules[0], BTT6200_CH3, true);
	  HAL_Delay(1000);
	  BTT6200_SetChannel(&btt6200_modules[1], BTT6200_CH0, true);
	  BTT6200_SetChannel(&btt6200_modules[1], BTT6200_CH1, true);
	  BTT6200_SetChannel(&btt6200_modules[1], BTT6200_CH2, true);
	  BTT6200_SetChannel(&btt6200_modules[1], BTT6200_CH3, true);
	  HAL_Delay(1000);
	  BTT6200_SetChannel(&btt6200_modules[2], BTT6200_CH0, true);
	  BTT6200_SetChannel(&btt6200_modules[2], BTT6200_CH1, true);
	  BTT6200_SetChannel(&btt6200_modules[2], BTT6200_CH2, true);
	  BTT6200_SetChannel(&btt6200_modules[2], BTT6200_CH3, true);
	  HAL_Delay(1000);
	  BTT6200_SetChannel(&btt6200_modules[3], BTT6200_CH0, true);
	  BTT6200_SetChannel(&btt6200_modules[3], BTT6200_CH1, true);
	  BTT6200_SetChannel(&btt6200_modules[3], BTT6200_CH2, true);
	  BTT6200_SetChannel(&btt6200_modules[3], BTT6200_CH3, true);
	  HAL_Delay(1000);
	  BTT6200_SetChannel(&btt6200_modules[4], BTT6200_CH0, true);
	  BTT6200_SetChannel(&btt6200_modules[4], BTT6200_CH1, true);
	  BTT6200_SetChannel(&btt6200_modules[4], BTT6200_CH2, true);
	  BTT6200_SetChannel(&btt6200_modules[4], BTT6200_CH3, true);
	  uint32_t i_mA;
	  if (BTT6200_ReadChannelCurrent(&btt6200_modules[1], BTT6200_CH1, &i_mA) == HAL_OK) {
	      // i_mA = tok v mA (po tvoji formuli v driverju)
	  }
#endif  /* TEST CODE */

  }
  /* USER CODE END 3 */
}

void SystemClock_Config(void)
{
  RCC_OscInitTypeDef RCC_OscInitStruct = {0};
  RCC_ClkInitTypeDef RCC_ClkInitStruct = {0};

  /** Configure the main internal regulator output voltage
  */
  __HAL_RCC_PWR_CLK_ENABLE();
  __HAL_PWR_VOLTAGESCALING_CONFIG(PWR_REGULATOR_VOLTAGE_SCALE1);

  /** Initializes the RCC Oscillators according to the specified parameters
  * in the RCC_OscInitTypeDef structure.
  */
  RCC_OscInitStruct.OscillatorType = RCC_OSCILLATORTYPE_HSI;
  RCC_OscInitStruct.HSIState = RCC_HSI_ON;
  RCC_OscInitStruct.HSICalibrationValue = RCC_HSICALIBRATION_DEFAULT;
  RCC_OscInitStruct.PLL.PLLState = RCC_PLL_NONE;
  if (HAL_RCC_OscConfig(&RCC_OscInitStruct) != HAL_OK)
  {
    Error_Handler();
  }

  /** Initializes the CPU, AHB and APB buses clocks
  */
  RCC_ClkInitStruct.ClockType = RCC_CLOCKTYPE_HCLK|RCC_CLOCKTYPE_SYSCLK
                              |RCC_CLOCKTYPE_PCLK1|RCC_CLOCKTYPE_PCLK2;
  RCC_ClkInitStruct.SYSCLKSource = RCC_SYSCLKSOURCE_HSI;
  RCC_ClkInitStruct.AHBCLKDivider = RCC_SYSCLK_DIV1;
  RCC_ClkInitStruct.APB1CLKDivider = RCC_HCLK_DIV1;
  RCC_ClkInitStruct.APB2CLKDivider = RCC_HCLK_DIV1;

  if (HAL_RCC_ClockConfig(&RCC_ClkInitStruct, FLASH_LATENCY_0) != HAL_OK)
  {
    Error_Handler();
  }
}

static void MX_ADC1_Init(void)
{

  ADC_ChannelConfTypeDef sConfig = {0};

  /** Configure the global features of the ADC (Clock, Resolution, Data Alignment and number of conversion)
  */
  hadc1.Instance = ADC1;
  hadc1.Init.ClockPrescaler = ADC_CLOCK_SYNC_PCLK_DIV2;
  hadc1.Init.Resolution = ADC_RESOLUTION_12B;
  hadc1.Init.ScanConvMode = ENABLE;                    // Enable for multiple channels
  hadc1.Init.ContinuousConvMode = ENABLE;              // Enable for continuous conversion
  hadc1.Init.DiscontinuousConvMode = DISABLE;
  hadc1.Init.ExternalTrigConvEdge = ADC_EXTERNALTRIGCONVEDGE_NONE;
  hadc1.Init.ExternalTrigConv = ADC_SOFTWARE_START;
  hadc1.Init.DataAlign = ADC_DATAALIGN_RIGHT;
  hadc1.Init.NbrOfConversion = 16;                     // 16 channels total
  hadc1.Init.DMAContinuousRequests = ENABLE;           // Enable DMA continuous requests
  hadc1.Init.EOCSelection = ADC_EOC_SEQ_CONV;          // End of sequence
  if (HAL_ADC_Init(&hadc1) != HAL_OK)
  {
    Error_Handler();
  }

  /** Configure all 16 ADC channels in sequence
   *  Channels mapped to:
   *  - IN0-IN9: LEM sensors 1-10 (PA0-PA7, PB0-PB1)
   *  - IN10-IN14: BTT6200 IS channels 0-4 (PC0-PC4)
   *  - IN15: Power current (PC5)
  */
  sConfig.SamplingTime = ADC_SAMPLETIME_15CYCLES;

  // LEM sensors (IN0-IN9)
  sConfig.Channel = ADC_CHANNEL_0; sConfig.Rank = 1;
  if (HAL_ADC_ConfigChannel(&hadc1, &sConfig) != HAL_OK) { Error_Handler(); }

  sConfig.Channel = ADC_CHANNEL_1; sConfig.Rank = 2;
  if (HAL_ADC_ConfigChannel(&hadc1, &sConfig) != HAL_OK) { Error_Handler(); }

  sConfig.Channel = ADC_CHANNEL_2; sConfig.Rank = 3;
  if (HAL_ADC_ConfigChannel(&hadc1, &sConfig) != HAL_OK) { Error_Handler(); }

  sConfig.Channel = ADC_CHANNEL_3; sConfig.Rank = 4;
  if (HAL_ADC_ConfigChannel(&hadc1, &sConfig) != HAL_OK) { Error_Handler(); }

  sConfig.Channel = ADC_CHANNEL_4; sConfig.Rank = 5;
  if (HAL_ADC_ConfigChannel(&hadc1, &sConfig) != HAL_OK) { Error_Handler(); }

  sConfig.Channel = ADC_CHANNEL_5; sConfig.Rank = 6;
  if (HAL_ADC_ConfigChannel(&hadc1, &sConfig) != HAL_OK) { Error_Handler(); }

  sConfig.Channel = ADC_CHANNEL_6; sConfig.Rank = 7;
  if (HAL_ADC_ConfigChannel(&hadc1, &sConfig) != HAL_OK) { Error_Handler(); }

  sConfig.Channel = ADC_CHANNEL_7; sConfig.Rank = 8;
  if (HAL_ADC_ConfigChannel(&hadc1, &sConfig) != HAL_OK) { Error_Handler(); }

  sConfig.Channel = ADC_CHANNEL_8; sConfig.Rank = 9;
  if (HAL_ADC_ConfigChannel(&hadc1, &sConfig) != HAL_OK) { Error_Handler(); }

  sConfig.Channel = ADC_CHANNEL_9; sConfig.Rank = 10;
  if (HAL_ADC_ConfigChannel(&hadc1, &sConfig) != HAL_OK) { Error_Handler(); }

  // BTT6200 IS channels (IN10-IN14)
  sConfig.Channel = ADC_CHANNEL_10; sConfig.Rank = 11;
  if (HAL_ADC_ConfigChannel(&hadc1, &sConfig) != HAL_OK) { Error_Handler(); }

  sConfig.Channel = ADC_CHANNEL_11; sConfig.Rank = 12;
  if (HAL_ADC_ConfigChannel(&hadc1, &sConfig) != HAL_OK) { Error_Handler(); }

  sConfig.Channel = ADC_CHANNEL_12; sConfig.Rank = 13;
  if (HAL_ADC_ConfigChannel(&hadc1, &sConfig) != HAL_OK) { Error_Handler(); }

  sConfig.Channel = ADC_CHANNEL_13; sConfig.Rank = 14;
  if (HAL_ADC_ConfigChannel(&hadc1, &sConfig) != HAL_OK) { Error_Handler(); }

  sConfig.Channel = ADC_CHANNEL_14; sConfig.Rank = 15;
  if (HAL_ADC_ConfigChannel(&hadc1, &sConfig) != HAL_OK) { Error_Handler(); }

  // Power current (IN15)
  sConfig.Channel = ADC_CHANNEL_15; sConfig.Rank = 16;
  if (HAL_ADC_ConfigChannel(&hadc1, &sConfig) != HAL_OK) { Error_Handler(); }

}

static void MX_CAN1_Init(void)
{

  hcan1.Instance = CAN1;
  hcan1.Init.Prescaler = 2;  // 500 kbps: 16MHz / (2 * 16) = 500 kbps
  hcan1.Init.Mode = CAN_MODE_NORMAL;
  hcan1.Init.SyncJumpWidth = CAN_SJW_1TQ;
  hcan1.Init.TimeSeg1 = CAN_BS1_13TQ;
  hcan1.Init.TimeSeg2 = CAN_BS2_2TQ;
  hcan1.Init.TimeTriggeredMode = DISABLE;
  hcan1.Init.AutoBusOff = ENABLE;  // Auto recovery iz bus-off
  hcan1.Init.AutoWakeUp = DISABLE;
  hcan1.Init.AutoRetransmission = ENABLE;  // Ponovno pošiljanje
  hcan1.Init.ReceiveFifoLocked = DISABLE;
  hcan1.Init.TransmitFifoPriority = DISABLE;
  if (HAL_CAN_Init(&hcan1) != HAL_OK)
  {
    Error_Handler();
  }

}

static void MX_CAN2_Init(void)
{

  hcan2.Instance = CAN2;
  hcan2.Init.Prescaler = 2;  // 500 kbps: 16MHz / (2 * 16) = 500 kbps
  hcan2.Init.Mode = CAN_MODE_NORMAL;
  hcan2.Init.SyncJumpWidth = CAN_SJW_1TQ;
  hcan2.Init.TimeSeg1 = CAN_BS1_13TQ;
  hcan2.Init.TimeSeg2 = CAN_BS2_2TQ;
  hcan2.Init.TimeTriggeredMode = DISABLE;
  hcan2.Init.AutoBusOff = ENABLE;  // Auto recovery iz bus-off
  hcan2.Init.AutoWakeUp = DISABLE;
  hcan2.Init.AutoRetransmission = ENABLE;  // Ponovno pošiljanje
  hcan2.Init.ReceiveFifoLocked = DISABLE;
  hcan2.Init.TransmitFifoPriority = DISABLE;
  if (HAL_CAN_Init(&hcan2) != HAL_OK)
  {
    Error_Handler();
  }

}

static void MX_I2C2_Init(void)
{

  hi2c2.Instance = I2C2;
  hi2c2.Init.ClockSpeed = 100000;
  hi2c2.Init.DutyCycle = I2C_DUTYCYCLE_2;
  hi2c2.Init.OwnAddress1 = 0;
  hi2c2.Init.AddressingMode = I2C_ADDRESSINGMODE_7BIT;
  hi2c2.Init.DualAddressMode = I2C_DUALADDRESS_DISABLE;
  hi2c2.Init.OwnAddress2 = 0;
  hi2c2.Init.GeneralCallMode = I2C_GENERALCALL_DISABLE;
  hi2c2.Init.NoStretchMode = I2C_NOSTRETCH_DISABLE;
  if (HAL_I2C_Init(&hi2c2) != HAL_OK)
  {
    Error_Handler();
  }

}

static void MX_SPI4_Init(void)
{

  /* SPI4 parameter configuration*/
  hspi4.Instance = SPI4;
  hspi4.Init.Mode = SPI_MODE_MASTER;
  hspi4.Init.Direction = SPI_DIRECTION_2LINES;
  hspi4.Init.DataSize = SPI_DATASIZE_8BIT;
  hspi4.Init.CLKPolarity = SPI_POLARITY_LOW;
  hspi4.Init.CLKPhase = SPI_PHASE_1EDGE;
  hspi4.Init.NSS = SPI_NSS_HARD_OUTPUT;
  hspi4.Init.BaudRatePrescaler = SPI_BAUDRATEPRESCALER_2;
  hspi4.Init.FirstBit = SPI_FIRSTBIT_MSB;
  hspi4.Init.TIMode = SPI_TIMODE_DISABLE;
  hspi4.Init.CRCCalculation = SPI_CRCCALCULATION_DISABLE;
  hspi4.Init.CRCPolynomial = 10;
  if (HAL_SPI_Init(&hspi4) != HAL_OK)
  {
    Error_Handler();
  }

}

static void MX_USART1_UART_Init(void)
{

  huart1.Instance = USART1;
  huart1.Init.BaudRate = 115200;
  huart1.Init.WordLength = UART_WORDLENGTH_8B;
  huart1.Init.StopBits = UART_STOPBITS_1;
  huart1.Init.Parity = UART_PARITY_NONE;
  huart1.Init.Mode = UART_MODE_TX_RX;
  huart1.Init.HwFlowCtl = UART_HWCONTROL_NONE;
  huart1.Init.OverSampling = UART_OVERSAMPLING_16;
  if (HAL_UART_Init(&huart1) != HAL_OK)
  {
    Error_Handler();
  }

}

static void MX_GPIO_Init(void)
{
  GPIO_InitTypeDef GPIO_InitStruct = {0};

  /* GPIO Ports Clock Enable */
  __HAL_RCC_GPIOE_CLK_ENABLE();
  __HAL_RCC_GPIOC_CLK_ENABLE();
  __HAL_RCC_GPIOF_CLK_ENABLE();
  __HAL_RCC_GPIOH_CLK_ENABLE();
  __HAL_RCC_GPIOA_CLK_ENABLE();
  __HAL_RCC_GPIOB_CLK_ENABLE();
  __HAL_RCC_GPIOG_CLK_ENABLE();
  __HAL_RCC_GPIOD_CLK_ENABLE();

  /*Configure GPIO pin Output Level */
  HAL_GPIO_WritePin(GPIOF, PWR_24V_EN_Pin|PWR_SLEEP_Pin, GPIO_PIN_RESET);

  /*Configure GPIO pin Output Level */
  HAL_GPIO_WritePin(GPIOE, EN_5V_Pin|EN_3V3A_Pin|DSEL1_0_Pin|OUT3_0_Pin
                          |OUT2_0_Pin|DSEL0_0_Pin|DEN_0_Pin|OUT1_0_Pin, GPIO_PIN_RESET);

  /*Configure GPIO pin Output Level */
  HAL_GPIO_WritePin(GPIOB, OUT0_0_Pin|DSEL1_1_Pin, GPIO_PIN_RESET);

  /*Configure GPIO pin Output Level */
  HAL_GPIO_WritePin(GPIOD, OUT3_1_Pin|OUT2_1_Pin|DSEL0_1_Pin|DEN_1_Pin
                          |OUT1_1_Pin|OUT0_1_Pin|DSEL1_2_Pin|OUT3_2_Pin
                          |OUT2_4_Pin|OUT3_4_Pin|DSEL1_4_Pin|ISOSPI_EN_Pin, GPIO_PIN_RESET);

  /*Configure GPIO pin Output Level */
  HAL_GPIO_WritePin(GPIOG, OUT2_2_Pin|DSEL0_2_Pin|DEN_2_Pin|OUT1_2_Pin
                          |OUT0_2_Pin|LED_Pin, GPIO_PIN_RESET);

  /*Configure GPIO pin Output Level */
  HAL_GPIO_WritePin(GPIOC, DEN_3_Pin|DSEL0_3_Pin|DSEL1_3_Pin|OUT1_4_Pin
                          |DEN_4_Pin|DSEL0_4_Pin, GPIO_PIN_RESET);

  /*Configure GPIO pin Output Level */
  HAL_GPIO_WritePin(GPIOA, OUT0_3_Pin|OUT1_3_Pin|OUT2_3_Pin|OUT3_3_Pin
                          |OUT0_4_Pin, GPIO_PIN_RESET);

  /*Configure GPIO pins : LEM_OC_6_Pin IN_11_Pin IN_10_Pin */
  GPIO_InitStruct.Pin = LEM_OC_6_Pin|IN_11_Pin|IN_10_Pin;
  GPIO_InitStruct.Mode = GPIO_MODE_INPUT;
  GPIO_InitStruct.Pull = GPIO_NOPULL;
  HAL_GPIO_Init(GPIOE, &GPIO_InitStruct);

  /*Configure GPIO pins : LEM_OC_5_Pin LEM_OC_4_Pin */
  GPIO_InitStruct.Pin = LEM_OC_5_Pin|LEM_OC_4_Pin;
  GPIO_InitStruct.Mode = GPIO_MODE_IT_RISING;
  GPIO_InitStruct.Pull = GPIO_NOPULL;
  HAL_GPIO_Init(GPIOC, &GPIO_InitStruct);

  /*Configure GPIO pins : IN_9_Pin IN_8_Pin IN_7_Pin IN_6_Pin
                           IN_5_Pin IN_4_Pin IN_3_Pin IN_2_Pin
                           IN_1_Pin PG_5V_Pin LEM_OC_8_Pin */
  GPIO_InitStruct.Pin = IN_9_Pin|IN_8_Pin|IN_7_Pin|IN_6_Pin
                          |IN_5_Pin|IN_4_Pin|IN_3_Pin|IN_2_Pin
                          |IN_1_Pin|PG_5V_Pin|LEM_OC_8_Pin;
  GPIO_InitStruct.Mode = GPIO_MODE_INPUT;
  GPIO_InitStruct.Pull = GPIO_NOPULL;
  HAL_GPIO_Init(GPIOF, &GPIO_InitStruct);

  /*Configure GPIO pins : PWR_FLT_Pin LEM_OC_2_Pin */
  GPIO_InitStruct.Pin = PWR_FLT_Pin|LEM_OC_2_Pin;
  GPIO_InitStruct.Mode = GPIO_MODE_IT_RISING;
  GPIO_InitStruct.Pull = GPIO_NOPULL;
  HAL_GPIO_Init(GPIOB, &GPIO_InitStruct);

  /*Configure GPIO pin : PG_3V3A_Pin */
  GPIO_InitStruct.Pin = PG_3V3A_Pin;
  GPIO_InitStruct.Mode = GPIO_MODE_IT_RISING;
  GPIO_InitStruct.Pull = GPIO_NOPULL;
  HAL_GPIO_Init(PG_3V3A_GPIO_Port, &GPIO_InitStruct);

  /*Configure GPIO pins : PWR_24V_EN_Pin PWR_SLEEP_Pin */
  GPIO_InitStruct.Pin = PWR_24V_EN_Pin|PWR_SLEEP_Pin;
  GPIO_InitStruct.Mode = GPIO_MODE_OUTPUT_PP;
  GPIO_InitStruct.Pull = GPIO_NOPULL;
  GPIO_InitStruct.Speed = GPIO_SPEED_FREQ_LOW;
  HAL_GPIO_Init(GPIOF, &GPIO_InitStruct);

  /*Configure GPIO pins : EN_5V_Pin EN_3V3A_Pin DSEL1_0_Pin OUT3_0_Pin
                           OUT2_0_Pin DSEL0_0_Pin DEN_0_Pin OUT1_0_Pin */
  GPIO_InitStruct.Pin = EN_5V_Pin|EN_3V3A_Pin|DSEL1_0_Pin|OUT3_0_Pin
                          |OUT2_0_Pin|DSEL0_0_Pin|DEN_0_Pin|OUT1_0_Pin;
  GPIO_InitStruct.Mode = GPIO_MODE_OUTPUT_PP;
  GPIO_InitStruct.Pull = GPIO_NOPULL;
  GPIO_InitStruct.Speed = GPIO_SPEED_FREQ_LOW;
  HAL_GPIO_Init(GPIOE, &GPIO_InitStruct);

  /*Configure GPIO pin : LEM_OC_7_Pin */
  GPIO_InitStruct.Pin = LEM_OC_7_Pin;
  GPIO_InitStruct.Mode = GPIO_MODE_IT_RISING;
  GPIO_InitStruct.Pull = GPIO_NOPULL;
  HAL_GPIO_Init(LEM_OC_7_GPIO_Port, &GPIO_InitStruct);

  /*Configure GPIO pins : OUT0_0_Pin DSEL1_1_Pin */
  GPIO_InitStruct.Pin = OUT0_0_Pin|DSEL1_1_Pin;
  GPIO_InitStruct.Mode = GPIO_MODE_OUTPUT_PP;
  GPIO_InitStruct.Pull = GPIO_NOPULL;
  GPIO_InitStruct.Speed = GPIO_SPEED_FREQ_LOW;
  HAL_GPIO_Init(GPIOB, &GPIO_InitStruct);

  /*Configure GPIO pins : LEM_OC_3_Pin IN_15_Pin IN_14_Pin IN_13_Pin
                           IN_12_Pin */
  GPIO_InitStruct.Pin = LEM_OC_3_Pin|IN_15_Pin|IN_14_Pin|IN_13_Pin
                          |IN_12_Pin;
  GPIO_InitStruct.Mode = GPIO_MODE_INPUT;
  GPIO_InitStruct.Pull = GPIO_NOPULL;
  HAL_GPIO_Init(GPIOB, &GPIO_InitStruct);

  /*Configure GPIO pins : OUT3_1_Pin OUT2_1_Pin DSEL0_1_Pin DEN_1_Pin
                           OUT1_1_Pin OUT0_1_Pin DSEL1_2_Pin OUT3_2_Pin
                           OUT2_4_Pin OUT3_4_Pin DSEL1_4_Pin ISOSPI_EN_Pin */
  GPIO_InitStruct.Pin = OUT3_1_Pin|OUT2_1_Pin|DSEL0_1_Pin|DEN_1_Pin
                          |OUT1_1_Pin|OUT0_1_Pin|DSEL1_2_Pin|OUT3_2_Pin
                          |OUT2_4_Pin|OUT3_4_Pin|DSEL1_4_Pin|ISOSPI_EN_Pin;
  GPIO_InitStruct.Mode = GPIO_MODE_OUTPUT_PP;
  GPIO_InitStruct.Pull = GPIO_NOPULL;
  GPIO_InitStruct.Speed = GPIO_SPEED_FREQ_LOW;
  HAL_GPIO_Init(GPIOD, &GPIO_InitStruct);

  /*Configure GPIO pins : OUT2_2_Pin DSEL0_2_Pin DEN_2_Pin OUT1_2_Pin
                           OUT0_2_Pin LED_Pin */
  GPIO_InitStruct.Pin = OUT2_2_Pin|DSEL0_2_Pin|DEN_2_Pin|OUT1_2_Pin
                          |OUT0_2_Pin|LED_Pin;
  GPIO_InitStruct.Mode = GPIO_MODE_OUTPUT_PP;
  GPIO_InitStruct.Pull = GPIO_NOPULL;
  GPIO_InitStruct.Speed = GPIO_SPEED_FREQ_LOW;
  HAL_GPIO_Init(GPIOG, &GPIO_InitStruct);

  /*Configure GPIO pins : LEM_OC_9_Pin LEM_OC_10_Pin */
  GPIO_InitStruct.Pin = LEM_OC_9_Pin|LEM_OC_10_Pin;
  GPIO_InitStruct.Mode = GPIO_MODE_IT_RISING;
  GPIO_InitStruct.Pull = GPIO_NOPULL;
  HAL_GPIO_Init(GPIOG, &GPIO_InitStruct);

  /*Configure GPIO pins : DEN_3_Pin DSEL0_3_Pin DSEL1_3_Pin OUT1_4_Pin
                           DEN_4_Pin DSEL0_4_Pin */
  GPIO_InitStruct.Pin = DEN_3_Pin|DSEL0_3_Pin|DSEL1_3_Pin|OUT1_4_Pin
                          |DEN_4_Pin|DSEL0_4_Pin;
  GPIO_InitStruct.Mode = GPIO_MODE_OUTPUT_PP;
  GPIO_InitStruct.Pull = GPIO_NOPULL;
  GPIO_InitStruct.Speed = GPIO_SPEED_FREQ_LOW;
  HAL_GPIO_Init(GPIOC, &GPIO_InitStruct);

  /*Configure GPIO pins : OUT0_3_Pin OUT1_3_Pin OUT2_3_Pin OUT3_3_Pin
                           OUT0_4_Pin */
  GPIO_InitStruct.Pin = OUT0_3_Pin|OUT1_3_Pin|OUT2_3_Pin|OUT3_3_Pin
                          |OUT0_4_Pin;
  GPIO_InitStruct.Mode = GPIO_MODE_OUTPUT_PP;
  GPIO_InitStruct.Pull = GPIO_NOPULL;
  GPIO_InitStruct.Speed = GPIO_SPEED_FREQ_LOW;
  HAL_GPIO_Init(GPIOA, &GPIO_InitStruct);

  /*Configure GPIO pin : LEM_OC_1_Pin */
  GPIO_InitStruct.Pin = LEM_OC_1_Pin;
  GPIO_InitStruct.Mode = GPIO_MODE_INPUT;
  GPIO_InitStruct.Pull = GPIO_NOPULL;
  HAL_GPIO_Init(LEM_OC_1_GPIO_Port, &GPIO_InitStruct);

  /*Configure GPIO pins : IN_20_Pin IN_19_Pin IN_18_Pin IN_17_Pin
                           IN_16_Pin */
  GPIO_InitStruct.Pin = IN_20_Pin|IN_19_Pin|IN_18_Pin|IN_17_Pin
                          |IN_16_Pin;
  GPIO_InitStruct.Mode = GPIO_MODE_INPUT;
  GPIO_InitStruct.Pull = GPIO_NOPULL;
  HAL_GPIO_Init(GPIOG, &GPIO_InitStruct);

}

/* USER CODE BEGIN 4 */

/* NOTE: HAL_CAN_RxFifo0MsgPendingCallback is now defined in stm32f4xx_it.c
 * It handles both DCDC and BMU protocols for CAN1 and CAN2 interrupts.
 * DO NOT duplicate this function here!
 */

/* USER CODE END 4 */

void Error_Handler(void)
{
  __disable_irq();
  while (1)
  {
  }
}
